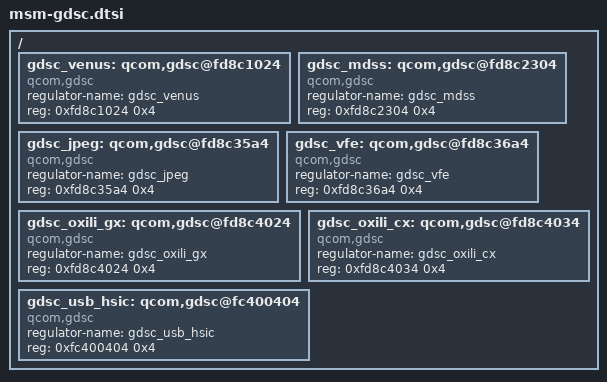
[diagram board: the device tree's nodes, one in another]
/*
 * Copyright (c) 2012, The Linux Foundation. All rights reserved.
 *
 * This program is free software; you can redistribute it and/or modify
 * it under the terms of the GNU General Public License version 2 and
 * only version 2 as published by the Free Software Foundation.
 *
 * This program is distributed in the hope that it will be useful,
 * but WITHOUT ANY WARRANTY; without even the implied warranty of
 * MERCHANTABILITY or FITNESS FOR A PARTICULAR PURPOSE.  See the
 * GNU General Public License for more details.
 */

/include/ "skeleton.dtsi"

/ {
	gdsc_venus: qcom,gdsc@fd8c1024 {
		compatible = "qcom,gdsc";
		regulator-name = "gdsc_venus";
		reg = <0xfd8c1024 0x4>;
	};

	gdsc_mdss: qcom,gdsc@fd8c2304 {
		compatible = "qcom,gdsc";
		regulator-name = "gdsc_mdss";
		reg = <0xfd8c2304 0x4>;
	};

	gdsc_jpeg: qcom,gdsc@fd8c35a4 {
		compatible = "qcom,gdsc";
		regulator-name = "gdsc_jpeg";
		reg = <0xfd8c35a4 0x4>;
	};

	gdsc_vfe: qcom,gdsc@fd8c36a4 {
		compatible = "qcom,gdsc";
		regulator-name = "gdsc_vfe";
		reg = <0xfd8c36a4 0x4>;
	};

	gdsc_oxili_gx: qcom,gdsc@fd8c4024 {
		compatible = "qcom,gdsc";
		regulator-name = "gdsc_oxili_gx";
		reg = <0xfd8c4024 0x4>;
	};

	gdsc_oxili_cx: qcom,gdsc@fd8c4034 {
		compatible = "qcom,gdsc";
		regulator-name = "gdsc_oxili_cx";
		reg = <0xfd8c4034 0x4>;
	};

	gdsc_usb_hsic: qcom,gdsc@fc400404 {
		compatible = "qcom,gdsc";
		regulator-name = "gdsc_usb_hsic";
		reg = <0xfc400404 0x4>;
	};
};
